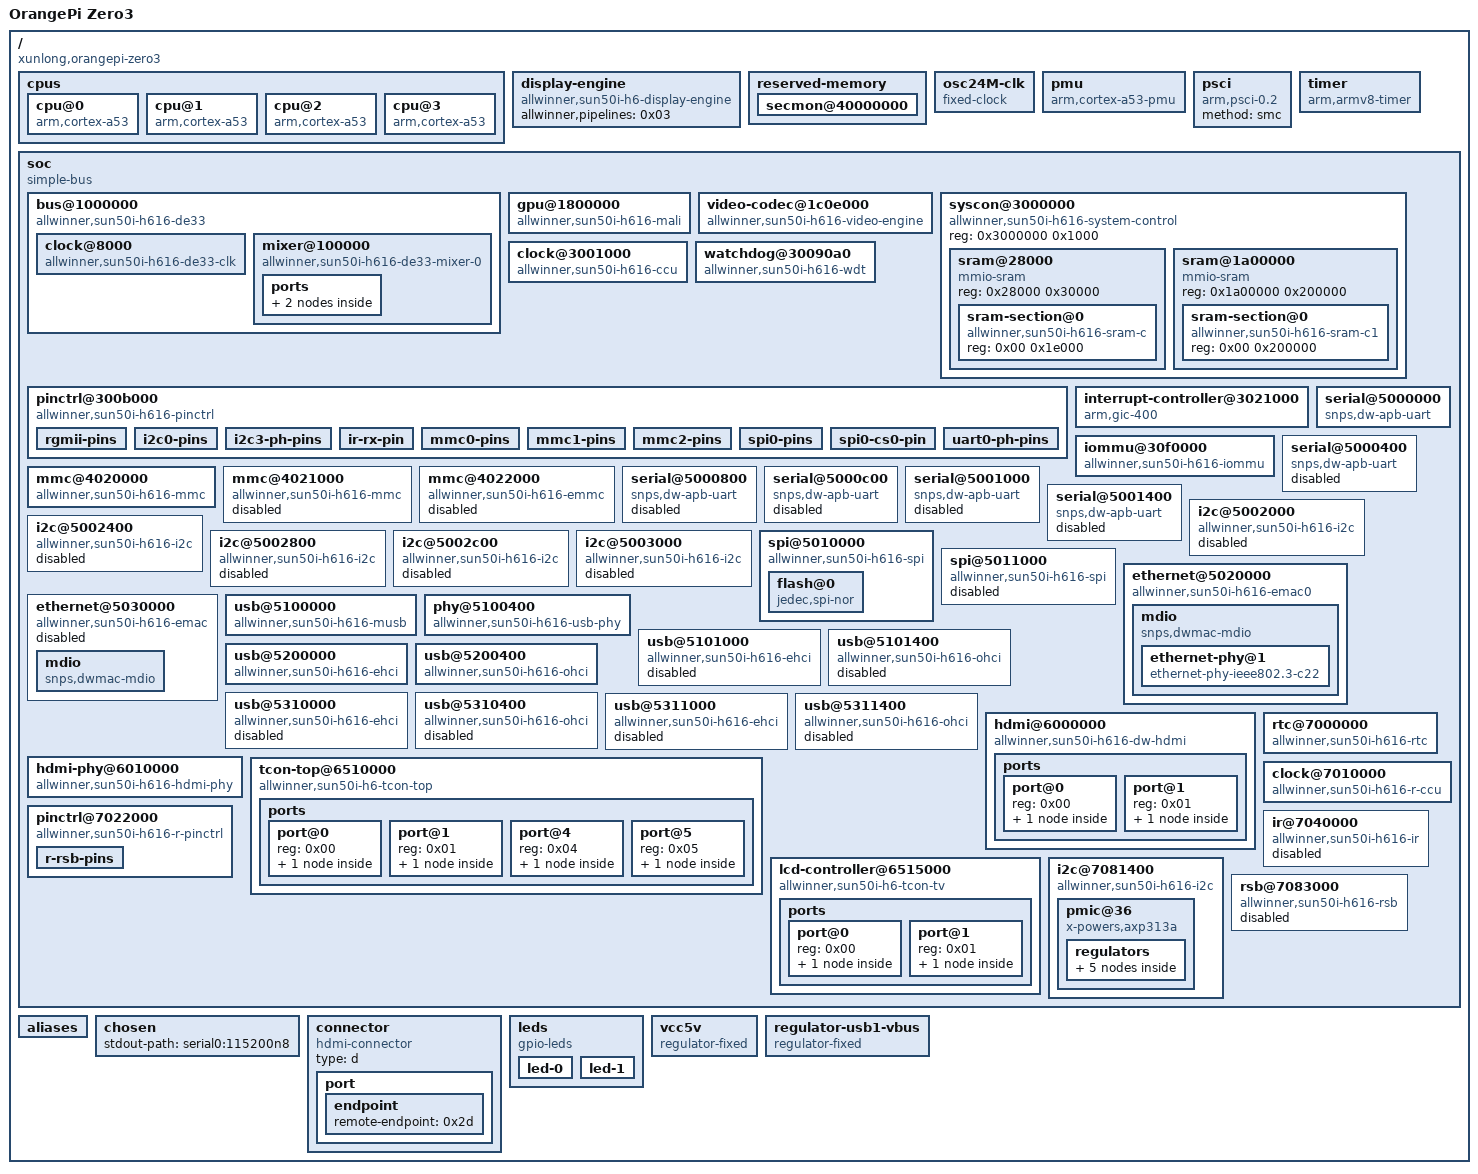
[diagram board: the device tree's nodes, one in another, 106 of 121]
/dts-v1/;

/ {
	interrupt-parent = <0x01>;
	#address-cells = <0x02>;
	#size-cells = <0x02>;
	model = "OrangePi Zero3";
	compatible = "xunlong,orangepi-zero3\0allwinner,sun50i-h618";

	cpus {
		#address-cells = <0x01>;
		#size-cells = <0x00>;

		cpu@0 {
			compatible = "arm,cortex-a53";
			device_type = "cpu";
			reg = <0x00>;
			enable-method = "psci";
			clocks = <0x02 0x15>;
			phandle = <0x04>;
		};

		cpu@1 {
			compatible = "arm,cortex-a53";
			device_type = "cpu";
			reg = <0x01>;
			enable-method = "psci";
			clocks = <0x02 0x15>;
			phandle = <0x05>;
		};

		cpu@2 {
			compatible = "arm,cortex-a53";
			device_type = "cpu";
			reg = <0x02>;
			enable-method = "psci";
			clocks = <0x02 0x15>;
			phandle = <0x06>;
		};

		cpu@3 {
			compatible = "arm,cortex-a53";
			device_type = "cpu";
			reg = <0x03>;
			enable-method = "psci";
			clocks = <0x02 0x15>;
			phandle = <0x07>;
		};
	};

	display-engine {
		compatible = "allwinner,sun50i-h6-display-engine";
		allwinner,pipelines = <0x03>;
		status = "okay";
	};

	reserved-memory {
		#address-cells = <0x02>;
		#size-cells = <0x02>;
		ranges;

		secmon@40000000 {
			reg = <0x00 0x40000000 0x00 0x40000>;
			no-map;
		};
	};

	osc24M-clk {
		#clock-cells = <0x00>;
		compatible = "fixed-clock";
		clock-frequency = <0x16e3600>;
		clock-output-names = "osc24M";
		phandle = <0x0e>;
	};

	pmu {
		compatible = "arm,cortex-a53-pmu";
		interrupts = <0x00 0x8c 0x04 0x00 0x8d 0x04 0x00 0x8e 0x04 0x00 0x8f 0x04>;
		interrupt-affinity = <0x04 0x05 0x06 0x07>;
	};

	psci {
		compatible = "arm,psci-0.2";
		method = "smc";
	};

	timer {
		compatible = "arm,armv8-timer";
		arm,no-tick-in-suspend;
		interrupts = <0x01 0x0d 0xf04 0x01 0x0e 0xf04 0x01 0x0b 0xf04 0x01 0x0a 0xf04>;
	};

	soc {
		compatible = "simple-bus";
		#address-cells = <0x01>;
		#size-cells = <0x01>;
		ranges = <0x00 0x00 0x00 0x40000000>;

		bus@1000000 {
			compatible = "allwinner,sun50i-h616-de33\0allwinner,sun50i-a64-de2";
			reg = <0x1000000 0x400000>;
			allwinner,sram = <0x08 0x01>;
			#address-cells = <0x01>;
			#size-cells = <0x01>;
			ranges = <0x00 0x1000000 0x400000>;

			clock@8000 {
				compatible = "allwinner,sun50i-h616-de33-clk";
				reg = <0x8000 0x100>;
				clocks = <0x02 0x1d 0x02 0x1e>;
				clock-names = "mod\0bus";
				resets = <0x02 0x01>;
				#clock-cells = <0x01>;
				#reset-cells = <0x01>;
				phandle = <0x09>;
			};

			mixer@100000 {
				compatible = "allwinner,sun50i-h616-de33-mixer-0";
				reg = <0x100000 0x100000 0x8100 0x40 0x280000 0x20000>;
				clocks = <0x09 0x00 0x09 0x06>;
				clock-names = "bus\0mod";
				resets = <0x09 0x00>;
				iommus = <0x0a 0x00>;
				phandle = <0x03>;

				ports {
					#address-cells = <0x01>;
					#size-cells = <0x00>;

					port@1 {
						reg = <0x01>;

						endpoint {
							remote-endpoint = <0x0b>;
							phandle = <0x22>;
						};
					};
				};
			};
		};

		gpu@1800000 {
			compatible = "allwinner,sun50i-h616-mali\0arm,mali-bifrost";
			reg = <0x1800000 0x40000>;
			interrupts = <0x00 0x5f 0x04 0x00 0x60 0x04 0x00 0x61 0x04>;
			interrupt-names = "job\0mmu\0gpu";
			clocks = <0x02 0x23 0x02 0x24>;
			clock-names = "core\0bus";
			resets = <0x02 0x03>;
			status = "okay";
			mali-supply = <0x0c>;
		};

		video-codec@1c0e000 {
			compatible = "allwinner,sun50i-h616-video-engine";
			reg = <0x1c0e000 0x2000>;
			clocks = <0x02 0x29 0x02 0x28 0x02 0x33>;
			clock-names = "ahb\0mod\0ram";
			resets = <0x02 0x05>;
			interrupts = <0x00 0x5d 0x04>;
			allwinner,sram = <0x0d 0x01>;
			iommus = <0x0a 0x02 0x0a 0x03>;
		};

		syscon@3000000 {
			compatible = "allwinner,sun50i-h616-system-control";
			reg = <0x3000000 0x1000>;
			#address-cells = <0x01>;
			#size-cells = <0x01>;
			ranges;
			phandle = <0x1a>;

			sram@28000 {
				compatible = "mmio-sram";
				reg = <0x28000 0x30000>;
				#address-cells = <0x01>;
				#size-cells = <0x01>;
				ranges = <0x00 0x28000 0x30000>;

				sram-section@0 {
					compatible = "allwinner,sun50i-h616-sram-c\0allwinner,sun50i-a64-sram-c";
					reg = <0x00 0x1e000>;
					phandle = <0x08>;
				};
			};

			sram@1a00000 {
				compatible = "mmio-sram";
				reg = <0x1a00000 0x200000>;
				#address-cells = <0x01>;
				#size-cells = <0x01>;
				ranges = <0x00 0x1a00000 0x200000>;

				sram-section@0 {
					compatible = "allwinner,sun50i-h616-sram-c1";
					reg = <0x00 0x200000>;
					phandle = <0x0d>;
				};
			};
		};

		clock@3001000 {
			compatible = "allwinner,sun50i-h616-ccu";
			reg = <0x3001000 0x1000>;
			clocks = <0x0e 0x0f 0x00 0x0f 0x02>;
			clock-names = "hosc\0losc\0iosc";
			#clock-cells = <0x01>;
			#reset-cells = <0x01>;
			phandle = <0x02>;
		};

		watchdog@30090a0 {
			compatible = "allwinner,sun50i-h616-wdt\0allwinner,sun6i-a31-wdt";
			reg = <0x30090a0 0x20>;
			interrupts = <0x00 0x32 0x04>;
			clocks = <0x0e>;
		};

		pinctrl@300b000 {
			compatible = "allwinner,sun50i-h616-pinctrl";
			reg = <0x300b000 0x400>;
			interrupts = <0x00 0x33 0x04 0x00 0x34 0x04 0x00 0x35 0x04 0x00 0x2b 0x04 0x00 0x36 0x04 0x00 0x37 0x04 0x00 0x38 0x04 0x00 0x39 0x04>;
			clocks = <0x02 0x1a 0x0e 0x0f 0x00>;
			clock-names = "apb\0hosc\0losc";
			gpio-controller;
			#gpio-cells = <0x03>;
			interrupt-controller;
			#interrupt-cells = <0x03>;
			vcc-pc-supply = <0x10>;
			vcc-pf-supply = <0x10>;
			vcc-pg-supply = <0x11>;
			vcc-ph-supply = <0x10>;
			vcc-pi-supply = <0x10>;
			phandle = <0x13>;

			rgmii-pins {
				pins = "PI0\0PI1\0PI2\0PI3\0PI4\0PI5\0PI7\0PI8\0PI9\0PI10\0PI11\0PI12\0PI13\0PI14\0PI15\0PI16";
				function = "emac0";
				drive-strength = <0x28>;
				phandle = <0x1b>;
			};

			i2c0-pins {
				pins = "PI6\0PI7";
				function = "i2c0";
				phandle = <0x17>;
			};

			i2c3-ph-pins {
				pins = "PH4\0PH5";
				function = "i2c3";
			};

			ir-rx-pin {
				pins = "PH10";
				function = "ir_rx";
				phandle = <0x2a>;
			};

			mmc0-pins {
				pins = "PF0\0PF1\0PF2\0PF3\0PF4\0PF5";
				function = "mmc0";
				drive-strength = <0x1e>;
				bias-pull-up;
				phandle = <0x12>;
			};

			mmc1-pins {
				pins = "PG0\0PG1\0PG2\0PG3\0PG4\0PG5";
				function = "mmc1";
				drive-strength = <0x1e>;
				bias-pull-up;
				phandle = <0x14>;
			};

			mmc2-pins {
				pins = "PC0\0PC1\0PC5\0PC6\0PC8\0PC9\0PC10\0PC11\0PC13\0PC14\0PC15\0PC16";
				function = "mmc2";
				drive-strength = <0x1e>;
				bias-pull-up;
				phandle = <0x15>;
			};

			spi0-pins {
				pins = "PC0\0PC2\0PC4";
				function = "spi0";
				phandle = <0x18>;
			};

			spi0-cs0-pin {
				pins = "PC3";
				function = "spi0";
				phandle = <0x19>;
			};

			uart0-ph-pins {
				pins = "PH0\0PH1";
				function = "uart0";
				phandle = <0x16>;
			};
		};

		interrupt-controller@3021000 {
			compatible = "arm,gic-400";
			reg = <0x3021000 0x1000 0x3022000 0x2000 0x3024000 0x2000 0x3026000 0x2000>;
			interrupts = <0x01 0x09 0xf04>;
			interrupt-controller;
			#interrupt-cells = <0x03>;
			phandle = <0x01>;
		};

		iommu@30f0000 {
			compatible = "allwinner,sun50i-h616-iommu\0allwinner,sun50i-h6-iommu";
			reg = <0x30f0000 0x10000>;
			interrupts = <0x00 0x3d 0x04>;
			clocks = <0x02 0x30>;
			resets = <0x02 0x0b>;
			#iommu-cells = <0x01>;
			status = "okay";
			phandle = <0x0a>;
		};

		mmc@4020000 {
			compatible = "allwinner,sun50i-h616-mmc\0allwinner,sun50i-a100-mmc";
			reg = <0x4020000 0x1000>;
			clocks = <0x02 0x3f 0x02 0x3c>;
			clock-names = "ahb\0mmc";
			resets = <0x02 0x0e>;
			reset-names = "ahb";
			interrupts = <0x00 0x23 0x04>;
			pinctrl-names = "default";
			pinctrl-0 = <0x12>;
			status = "okay";
			max-frequency = <0x8f0d180>;
			cap-sd-highspeed;
			cap-mmc-highspeed;
			mmc-ddr-3_3v;
			cap-sdio-irq;
			#address-cells = <0x01>;
			#size-cells = <0x00>;
			cd-gpios = <0x13 0x05 0x06 0x01>;
			bus-width = <0x04>;
			broken-cd;
			vmmc-supply = <0x10>;
		};

		mmc@4021000 {
			compatible = "allwinner,sun50i-h616-mmc\0allwinner,sun50i-a100-mmc";
			reg = <0x4021000 0x1000>;
			clocks = <0x02 0x40 0x02 0x3d>;
			clock-names = "ahb\0mmc";
			resets = <0x02 0x0f>;
			reset-names = "ahb";
			interrupts = <0x00 0x24 0x04>;
			pinctrl-names = "default";
			pinctrl-0 = <0x14>;
			status = "disabled";
			max-frequency = <0x8f0d180>;
			cap-sd-highspeed;
			cap-mmc-highspeed;
			mmc-ddr-3_3v;
			cap-sdio-irq;
			#address-cells = <0x01>;
			#size-cells = <0x00>;
		};

		mmc@4022000 {
			compatible = "allwinner,sun50i-h616-emmc\0allwinner,sun50i-a100-emmc";
			reg = <0x4022000 0x1000>;
			clocks = <0x02 0x41 0x02 0x3e>;
			clock-names = "ahb\0mmc";
			resets = <0x02 0x10>;
			reset-names = "ahb";
			interrupts = <0x00 0x25 0x04>;
			pinctrl-names = "default";
			pinctrl-0 = <0x15>;
			status = "disabled";
			max-frequency = <0x8f0d180>;
			cap-sd-highspeed;
			cap-mmc-highspeed;
			mmc-ddr-3_3v;
			cap-sdio-irq;
			#address-cells = <0x01>;
			#size-cells = <0x00>;
		};

		serial@5000000 {
			compatible = "snps,dw-apb-uart";
			reg = <0x5000000 0x400>;
			interrupts = <0x00 0x00 0x04>;
			reg-shift = <0x02>;
			reg-io-width = <0x04>;
			clocks = <0x02 0x42>;
			resets = <0x02 0x11>;
			status = "okay";
			pinctrl-names = "default";
			pinctrl-0 = <0x16>;
		};

		serial@5000400 {
			compatible = "snps,dw-apb-uart";
			reg = <0x5000400 0x400>;
			interrupts = <0x00 0x01 0x04>;
			reg-shift = <0x02>;
			reg-io-width = <0x04>;
			clocks = <0x02 0x43>;
			resets = <0x02 0x12>;
			status = "disabled";
		};

		serial@5000800 {
			compatible = "snps,dw-apb-uart";
			reg = <0x5000800 0x400>;
			interrupts = <0x00 0x02 0x04>;
			reg-shift = <0x02>;
			reg-io-width = <0x04>;
			clocks = <0x02 0x44>;
			resets = <0x02 0x13>;
			status = "disabled";
		};

		serial@5000c00 {
			compatible = "snps,dw-apb-uart";
			reg = <0x5000c00 0x400>;
			interrupts = <0x00 0x03 0x04>;
			reg-shift = <0x02>;
			reg-io-width = <0x04>;
			clocks = <0x02 0x45>;
			resets = <0x02 0x14>;
			status = "disabled";
		};

		serial@5001000 {
			compatible = "snps,dw-apb-uart";
			reg = <0x5001000 0x400>;
			interrupts = <0x00 0x04 0x04>;
			reg-shift = <0x02>;
			reg-io-width = <0x04>;
			clocks = <0x02 0x46>;
			resets = <0x02 0x15>;
			status = "disabled";
		};

		serial@5001400 {
			compatible = "snps,dw-apb-uart";
			reg = <0x5001400 0x400>;
			interrupts = <0x00 0x05 0x04>;
			reg-shift = <0x02>;
			reg-io-width = <0x04>;
			clocks = <0x02 0x47>;
			resets = <0x02 0x16>;
			status = "disabled";
		};

		i2c@5002000 {
			compatible = "allwinner,sun50i-h616-i2c\0allwinner,sun8i-v536-i2c\0allwinner,sun6i-a31-i2c";
			reg = <0x5002000 0x400>;
			interrupts = <0x00 0x06 0x04>;
			clocks = <0x02 0x48>;
			resets = <0x02 0x17>;
			pinctrl-names = "default";
			pinctrl-0 = <0x17>;
			status = "disabled";
			#address-cells = <0x01>;
			#size-cells = <0x00>;
		};

		i2c@5002400 {
			compatible = "allwinner,sun50i-h616-i2c\0allwinner,sun8i-v536-i2c\0allwinner,sun6i-a31-i2c";
			reg = <0x5002400 0x400>;
			interrupts = <0x00 0x07 0x04>;
			clocks = <0x02 0x49>;
			resets = <0x02 0x18>;
			status = "disabled";
			#address-cells = <0x01>;
			#size-cells = <0x00>;
		};

		i2c@5002800 {
			compatible = "allwinner,sun50i-h616-i2c\0allwinner,sun8i-v536-i2c\0allwinner,sun6i-a31-i2c";
			reg = <0x5002800 0x400>;
			interrupts = <0x00 0x08 0x04>;
			clocks = <0x02 0x4a>;
			resets = <0x02 0x19>;
			status = "disabled";
			#address-cells = <0x01>;
			#size-cells = <0x00>;
		};

		i2c@5002c00 {
			compatible = "allwinner,sun50i-h616-i2c\0allwinner,sun8i-v536-i2c\0allwinner,sun6i-a31-i2c";
			reg = <0x5002c00 0x400>;
			interrupts = <0x00 0x09 0x04>;
			clocks = <0x02 0x4b>;
			resets = <0x02 0x1a>;
			status = "disabled";
			#address-cells = <0x01>;
			#size-cells = <0x00>;
		};

		i2c@5003000 {
			compatible = "allwinner,sun50i-h616-i2c\0allwinner,sun8i-v536-i2c\0allwinner,sun6i-a31-i2c";
			reg = <0x5003000 0x400>;
			interrupts = <0x00 0x0a 0x04>;
			clocks = <0x02 0x4c>;
			resets = <0x02 0x1b>;
			status = "disabled";
			#address-cells = <0x01>;
			#size-cells = <0x00>;
		};

		spi@5010000 {
			compatible = "allwinner,sun50i-h616-spi\0allwinner,sun8i-h3-spi";
			reg = <0x5010000 0x1000>;
			interrupts = <0x00 0x0c 0x04>;
			clocks = <0x02 0x4f 0x02 0x4d>;
			clock-names = "ahb\0mod";
			resets = <0x02 0x1c>;
			status = "okay";
			#address-cells = <0x01>;
			#size-cells = <0x00>;
			pinctrl-names = "default";
			pinctrl-0 = <0x18 0x19>;

			flash@0 {
				#address-cells = <0x01>;
				#size-cells = <0x01>;
				compatible = "jedec,spi-nor";
				reg = <0x00>;
				spi-max-frequency = <0x2625a00>;
			};
		};

		spi@5011000 {
			compatible = "allwinner,sun50i-h616-spi\0allwinner,sun8i-h3-spi";
			reg = <0x5011000 0x1000>;
			interrupts = <0x00 0x0d 0x04>;
			clocks = <0x02 0x50 0x02 0x4e>;
			clock-names = "ahb\0mod";
			resets = <0x02 0x1d>;
			status = "disabled";
			#address-cells = <0x01>;
			#size-cells = <0x00>;
		};

		ethernet@5020000 {
			compatible = "allwinner,sun50i-h616-emac0\0allwinner,sun50i-a64-emac";
			reg = <0x5020000 0x10000>;
			interrupts = <0x00 0x0e 0x04>;
			interrupt-names = "macirq";
			clocks = <0x02 0x52>;
			clock-names = "stmmaceth";
			resets = <0x02 0x1e>;
			reset-names = "stmmaceth";
			syscon = <0x1a>;
			status = "okay";
			pinctrl-names = "default";
			pinctrl-0 = <0x1b>;
			phy-handle = <0x1c>;
			allwinner,tx-delay-ps = <0x2bc>;
			phy-mode = "rgmii-rxid";
			phy-supply = <0x10>;

			mdio {
				compatible = "snps,dwmac-mdio";
				#address-cells = <0x01>;
				#size-cells = <0x00>;

				ethernet-phy@1 {
					compatible = "ethernet-phy-ieee802.3-c22";
					reg = <0x01>;
					motorcomm,clk-out-frequency-hz = <0x7735940>;
					phandle = <0x1c>;
				};
			};
		};

		ethernet@5030000 {
			compatible = "allwinner,sun50i-h616-emac";
			syscon = <0x1a 0x01>;
			reg = <0x5030000 0x10000>;
			interrupts = <0x00 0x0f 0x04>;
			interrupt-names = "macirq";
			resets = <0x02 0x1f>;
			reset-names = "stmmaceth";
			clocks = <0x02 0x53>;
			clock-names = "stmmaceth";
			status = "disabled";

			mdio {
				compatible = "snps,dwmac-mdio";
				#address-cells = <0x01>;
				#size-cells = <0x00>;
			};
		};

		usb@5100000 {
			compatible = "allwinner,sun50i-h616-musb\0allwinner,sun8i-h3-musb";
			reg = <0x5100000 0x400>;
			clocks = <0x02 0x70>;
			resets = <0x02 0x32>;
			interrupts = <0x00 0x19 0x04>;
			interrupt-names = "mc";
			phys = <0x1d 0x00>;
			phy-names = "usb";
			extcon = <0x1d 0x00>;
			status = "okay";
			dr_mode = "peripheral";
		};

		phy@5100400 {
			compatible = "allwinner,sun50i-h616-usb-phy";
			reg = <0x5100400 0x24 0x5101800 0x14 0x5200800 0x14 0x5310800 0x14 0x5311800 0x14>;
			reg-names = "phy_ctrl\0pmu0\0pmu1\0pmu2\0pmu3";
			clocks = <0x02 0x61 0x02 0x63 0x02 0x65 0x02 0x67 0x02 0x6e>;
			clock-names = "usb0_phy\0usb1_phy\0usb2_phy\0usb3_phy\0pmu2_clk";
			resets = <0x02 0x26 0x02 0x27 0x02 0x28 0x02 0x29>;
			reset-names = "usb0_reset\0usb1_reset\0usb2_reset\0usb3_reset";
			status = "okay";
			#phy-cells = <0x01>;
			usb1_vbus-supply = <0x1e>;
			phandle = <0x1d>;
		};

		usb@5101000 {
			compatible = "allwinner,sun50i-h616-ehci\0generic-ehci";
			reg = <0x5101000 0x100>;
			interrupts = <0x00 0x1a 0x04>;
			clocks = <0x02 0x68 0x02 0x6c 0x02 0x60>;
			resets = <0x02 0x2a 0x02 0x2e>;
			phys = <0x1d 0x00>;
			phy-names = "usb";
			status = "disabled";
		};

		usb@5101400 {
			compatible = "allwinner,sun50i-h616-ohci\0generic-ohci";
			reg = <0x5101400 0x100>;
			interrupts = <0x00 0x1b 0x04>;
			clocks = <0x02 0x68 0x02 0x60>;
			resets = <0x02 0x2a>;
			phys = <0x1d 0x00>;
			phy-names = "usb";
			status = "disabled";
		};

		usb@5200000 {
			compatible = "allwinner,sun50i-h616-ehci\0generic-ehci";
			reg = <0x5200000 0x100>;
			interrupts = <0x00 0x1c 0x04>;
			clocks = <0x02 0x69 0x02 0x6d 0x02 0x62>;
			resets = <0x02 0x2b 0x02 0x2f>;
			phys = <0x1d 0x01>;
			phy-names = "usb";
			status = "okay";
		};

		usb@5200400 {
			compatible = "allwinner,sun50i-h616-ohci\0generic-ohci";
			reg = <0x5200400 0x100>;
			interrupts = <0x00 0x1d 0x04>;
			clocks = <0x02 0x69 0x02 0x62>;
			resets = <0x02 0x2b>;
			phys = <0x1d 0x01>;
			phy-names = "usb";
			status = "okay";
		};

		usb@5310000 {
			compatible = "allwinner,sun50i-h616-ehci\0generic-ehci";
			reg = <0x5310000 0x100>;
			interrupts = <0x00 0x1e 0x04>;
			clocks = <0x02 0x6a 0x02 0x6e 0x02 0x64>;
			resets = <0x02 0x2c 0x02 0x30>;
			phys = <0x1d 0x02>;
			phy-names = "usb";
			status = "disabled";
		};

		usb@5310400 {
			compatible = "allwinner,sun50i-h616-ohci\0generic-ohci";
			reg = <0x5310400 0x100>;
			interrupts = <0x00 0x1f 0x04>;
			clocks = <0x02 0x6a 0x02 0x64>;
			resets = <0x02 0x2c>;
			phys = <0x1d 0x02>;
			phy-names = "usb";
			status = "disabled";
		};

		usb@5311000 {
			compatible = "allwinner,sun50i-h616-ehci\0generic-ehci";
			reg = <0x5311000 0x100>;
			interrupts = <0x00 0x20 0x04>;
			clocks = <0x02 0x6b 0x02 0x6f 0x02 0x66>;
			resets = <0x02 0x2d 0x02 0x31>;
			phys = <0x1d 0x03>;
			phy-names = "usb";
			status = "disabled";
		};

		usb@5311400 {
			compatible = "allwinner,sun50i-h616-ohci\0generic-ohci";
			reg = <0x5311400 0x100>;
			interrupts = <0x00 0x21 0x04>;
			clocks = <0x02 0x6b 0x02 0x66>;
			resets = <0x02 0x2d>;
			phys = <0x1d 0x03>;
			phy-names = "usb";
			status = "disabled";
		};

		hdmi@6000000 {
			compatible = "allwinner,sun50i-h616-dw-hdmi\0allwinner,sun50i-h6-dw-hdmi";
			reg = <0x6000000 0x10000>;
			reg-io-width = <0x01>;
			interrupts = <0x00 0x3f 0x04>;
			clocks = <0x02 0x75 0x02 0x73 0x02 0x72 0x02 0x74 0x02 0x7e 0x02 0x7f>;
			clock-names = "iahb\0isfr\0tmds\0cec\0hdcp\0hdcp-bus";
			resets = <0x02 0x33 0x02 0x3a>;
			reset-names = "ctrl\0hdcp";
			phys = <0x1f>;
			phy-names = "phy";
			status = "okay";
			hvcc-supply = <0x11>;

			ports {
				#address-cells = <0x01>;
				#size-cells = <0x00>;

				port@0 {
					reg = <0x00>;

					endpoint {
						remote-endpoint = <0x20>;
						phandle = <0x25>;
					};
				};

				port@1 {
					reg = <0x01>;

					endpoint {
						remote-endpoint = <0x21>;
						phandle = <0x2d>;
					};
				};
			};
		};

		hdmi-phy@6010000 {
			compatible = "allwinner,sun50i-h616-hdmi-phy";
			reg = <0x6010000 0x10000>;
			clocks = <0x02 0x75 0x02 0x73>;
			clock-names = "bus\0mod";
			resets = <0x02 0x34>;
			reset-names = "phy";
			#phy-cells = <0x00>;
			phandle = <0x1f>;
		};

		tcon-top@6510000 {
			compatible = "allwinner,sun50i-h6-tcon-top";
			reg = <0x6510000 0x1000>;
			clocks = <0x02 0x76 0x02 0x77>;
			clock-names = "bus\0tcon-tv0";
			clock-output-names = "tcon-top-tv0";
			resets = <0x02 0x35>;
			#clock-cells = <0x01>;
			phandle = <0x26>;

			ports {
				#address-cells = <0x01>;
				#size-cells = <0x00>;

				port@0 {
					#address-cells = <0x01>;
					#size-cells = <0x00>;
					reg = <0x00>;

					endpoint@0 {
						reg = <0x00>;
						remote-endpoint = <0x22>;
						phandle = <0x0b>;
					};
				};

				port@1 {
					#address-cells = <0x01>;
					#size-cells = <0x00>;
					reg = <0x01>;

					endpoint@2 {
						reg = <0x02>;
						remote-endpoint = <0x23>;
						phandle = <0x27>;
					};
				};

				port@4 {
					#address-cells = <0x01>;
					#size-cells = <0x00>;
					reg = <0x04>;

					endpoint@0 {
						reg = <0x00>;
						remote-endpoint = <0x24>;
						phandle = <0x28>;
					};
				};

				port@5 {
					reg = <0x05>;

					endpoint {
						remote-endpoint = <0x25>;
						phandle = <0x20>;
					};
				};
			};
		};

		lcd-controller@6515000 {
			compatible = "allwinner,sun50i-h6-tcon-tv\0allwinner,sun8i-r40-tcon-tv";
			reg = <0x6515000 0x1000>;
			interrupts = <0x00 0x42 0x04>;
			clocks = <0x02 0x79 0x26 0x00>;
			clock-names = "ahb\0tcon-ch1";
			resets = <0x02 0x36>;
			reset-names = "lcd";

			ports {
				#address-cells = <0x01>;
				#size-cells = <0x00>;

				port@0 {
					reg = <0x00>;

					endpoint {
						remote-endpoint = <0x27>;
						phandle = <0x23>;
					};
				};

				port@1 {
					#address-cells = <0x01>;
					#size-cells = <0x00>;
					reg = <0x01>;

					endpoint@1 {
						reg = <0x01>;
						remote-endpoint = <0x28>;
						phandle = <0x24>;
					};
				};
			};
		};

		rtc@7000000 {
			compatible = "allwinner,sun50i-h616-rtc";
			reg = <0x7000000 0x400>;
			interrupts = <0x00 0x68 0x04>;
			clocks = <0x29 0x0e 0x0e 0x02 0x80>;
			clock-names = "bus\0hosc\0pll-32k";
			#clock-cells = <0x01>;
			phandle = <0x0f>;
		};

		clock@7010000 {
			compatible = "allwinner,sun50i-h616-r-ccu";
			reg = <0x7010000 0x210>;
			clocks = <0x0e 0x0f 0x00 0x0f 0x02 0x02 0x04>;
			clock-names = "hosc\0losc\0iosc\0pll-periph";
			#clock-cells = <0x01>;
			#reset-cells = <0x01>;
			phandle = <0x29>;
		};

		pinctrl@7022000 {
			compatible = "allwinner,sun50i-h616-r-pinctrl";
			reg = <0x7022000 0x400>;
			clocks = <0x29 0x02 0x0e 0x0f 0x00>;
			clock-names = "apb\0hosc\0losc";
			gpio-controller;
			#gpio-cells = <0x03>;

			r-rsb-pins {
				pins = "PL0\0PL1";
				function = "s_rsb";
				phandle = <0x2c>;
			};
		};

		ir@7040000 {
			compatible = "allwinner,sun50i-h616-ir\0allwinner,sun6i-a31-ir";
			reg = <0x7040000 0x400>;
			interrupts = <0x00 0x6a 0x04>;
			clocks = <0x29 0x09 0x29 0x0b>;
			clock-names = "apb\0ir";
			resets = <0x29 0x05>;
			pinctrl-names = "default";
			pinctrl-0 = <0x2a>;
			status = "disabled";
		};

		i2c@7081400 {
			compatible = "allwinner,sun50i-h616-i2c\0allwinner,sun8i-v536-i2c\0allwinner,sun6i-a31-i2c";
			reg = <0x7081400 0x400>;
			interrupts = <0x00 0x69 0x04>;
			clocks = <0x29 0x08>;
			resets = <0x29 0x04>;
			status = "okay";
			#address-cells = <0x01>;
			#size-cells = <0x00>;

			pmic@36 {
				compatible = "x-powers,axp313a";
				reg = <0x36>;
				#interrupt-cells = <0x01>;
				interrupt-controller;
				interrupt-parent = <0x13>;
				interrupts = <0x02 0x09 0x08>;
				vin1-supply = <0x2b>;
				vin2-supply = <0x2b>;
				vin3-supply = <0x2b>;

				regulators {

					aldo1 {
						regulator-always-on;
						regulator-min-microvolt = <0x1b7740>;
						regulator-max-microvolt = <0x1b7740>;
						regulator-name = "vcc1v8";
						phandle = <0x11>;
					};

					dldo1 {
						regulator-always-on;
						regulator-min-microvolt = <0x325aa0>;
						regulator-max-microvolt = <0x325aa0>;
						regulator-name = "vcc3v3";
						phandle = <0x10>;
					};

					dcdc1 {
						regulator-always-on;
						regulator-min-microvolt = <0xc5c10>;
						regulator-max-microvolt = <0xf1b30>;
						regulator-name = "vdd-gpu-sys";
						phandle = <0x0c>;
					};

					dcdc2 {
						regulator-always-on;
						regulator-min-microvolt = <0xc5c10>;
						regulator-max-microvolt = <0x10c8e0>;
						regulator-name = "vdd-cpu";
					};

					dcdc3 {
						regulator-always-on;
						regulator-min-microvolt = <0x10c8e0>;
						regulator-max-microvolt = <0x10c8e0>;
						regulator-name = "vdd-dram";
					};
				};
			};
		};

		rsb@7083000 {
			compatible = "allwinner,sun50i-h616-rsb\0allwinner,sun8i-a23-rsb";
			reg = <0x7083000 0x400>;
			interrupts = <0x00 0x6d 0x04>;
			clocks = <0x29 0x0d>;
			clock-frequency = <0x2dc6c0>;
			resets = <0x29 0x07>;
			pinctrl-names = "default";
			pinctrl-0 = <0x2c>;
			status = "disabled";
			#address-cells = <0x01>;
			#size-cells = <0x00>;
		};
	};

	aliases {
		ethernet0 = "/soc/ethernet@5020000";
		serial0 = "/soc/serial@5000000";
	};

	chosen {
		stdout-path = "serial0:115200n8";
	};

	connector {
		compatible = "hdmi-connector";
		type = "d";

		port {

			endpoint {
				remote-endpoint = <0x2d>;
				phandle = <0x21>;
			};
		};
	};

	leds {
		compatible = "gpio-leds";

		led-0 {
			function = "power";
			color = <0x01>;
			gpios = <0x13 0x02 0x0c 0x00>;
			default-state = "on";
		};

		led-1 {
			function = "status";
			color = <0x02>;
			gpios = <0x13 0x02 0x0d 0x00>;
		};
	};

	vcc5v {
		compatible = "regulator-fixed";
		regulator-name = "vcc-5v";
		regulator-min-microvolt = <0x4c4b40>;
		regulator-max-microvolt = <0x4c4b40>;
		regulator-always-on;
		phandle = <0x2b>;
	};

	regulator-usb1-vbus {
		compatible = "regulator-fixed";
		regulator-name = "usb1-vbus";
		regulator-min-microvolt = <0x4c4b40>;
		regulator-max-microvolt = <0x4c4b40>;
		vin-supply = <0x2b>;
		enable-active-high;
		gpio = <0x13 0x02 0x10 0x00>;
		phandle = <0x1e>;
	};
};
